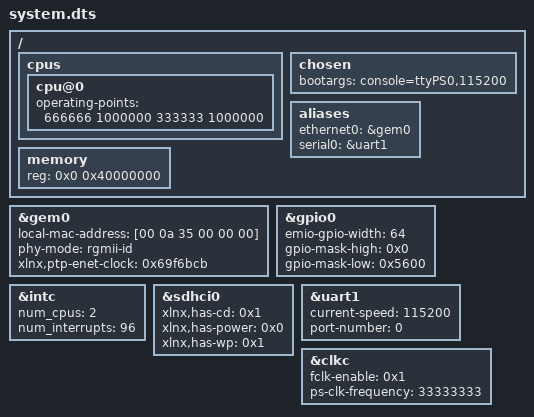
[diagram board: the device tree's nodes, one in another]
/*
 * CAUTION: This file is automatically generated by Xilinx.
 * Version:  
 * Today is: Thu Aug 11 22:00:13 2016
*/


/dts-v1/;
/include/ "zynq-7000.dtsi"
/include/ "pl.dtsi"
/ {
	cpus {
		cpu@0 {
			operating-points = <666666 1000000 333333 1000000>;
		};
	};
	chosen {
		bootargs = "console=ttyPS0,115200";
	};
	aliases {
		ethernet0 = &gem0;
		serial0 = &uart1;
	};
	memory {
		device_type = "memory";
		reg = <0x0 0x40000000>;
	};
};
&gem0 {
	local-mac-address = [00 0a 35 00 00 00];
	phy-mode = "rgmii-id";
	status = "okay";
	xlnx,ptp-enet-clock = <0x69f6bcb>;
};
&gpio0 {
	emio-gpio-width = <64>;
	gpio-mask-high = <0x0>;
	gpio-mask-low = <0x5600>;
};
&intc {
	num_cpus = <2>;
	num_interrupts = <96>;
};
&sdhci0 {
	status = "okay";
	xlnx,has-cd = <0x1>;
	xlnx,has-power = <0x0>;
	xlnx,has-wp = <0x1>;
};
&uart1 {
	current-speed = <115200>;
	device_type = "serial";
	port-number = <0>;
	status = "okay";
};
&clkc {
	fclk-enable = <0x1>;
	ps-clk-frequency = <33333333>;
};
